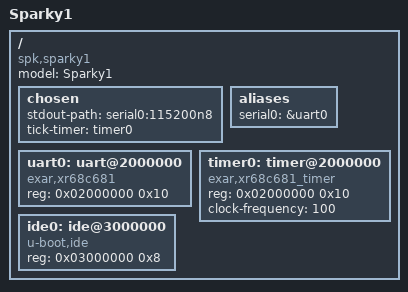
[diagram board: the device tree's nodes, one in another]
// SPDX-License-Identifier: GPL-2.0+
/*
 * Copyright (C) 2023 Graeme Harker (<graeme.harker@gmail.com>)
 */

/dts-v1/;

/ {
	model = "Sparky1";
	compatible = "spk,sparky1";
	#address-cells = <1>;
	#size-cells = <1>;

	chosen {
		stdout-path = "serial0:115200n8";
		tick-timer = "timer0";
	};

	aliases {
		serial0 = &uart0;
	};

    uart0: uart@2000000 {
        compatible = "exar,xr68c681";
        reg = <0x02000000 0x10>;
		status = "okay";
		bootph-all;
    };

    timer0: timer@2000000 {
        compatible = "exar,xr68c681_timer";
        reg = <0x02000000 0x10>;
		clock-frequency = <100>;
		status = "okay";
		bootph-all;
    };

    /*
     * CompactFlash in True IDE mode: 8 byte-wide registers selected by
     * A2-A0, on an 8-bit port at D31-D24. /DISKCS and the ATA strobes come
     * from plds/cfmanager in the sparky1 hardware project.
     *
     * The generic IDE driver takes its addressing from CONFIG_SYS_ATA_*,
     * so this node exists to bind the driver and to record the hardware;
     * reg is not read back by the driver.
     */
    ide0: ide@3000000 {
        compatible = "u-boot,ide";
        reg = <0x03000000 0x8>;
        status = "okay";
    };
};
